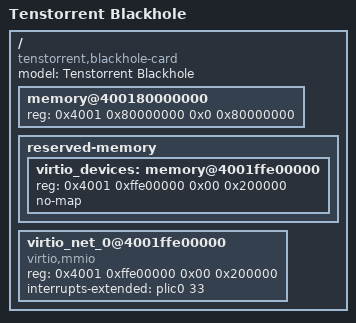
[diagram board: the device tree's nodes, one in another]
// SPDX-License-Identifier: (GPL-2.0 OR MIT)
/dts-v1/;

#include "blackhole.dtsi"

/ {
	model = "Tenstorrent Blackhole";
	compatible = "tenstorrent,blackhole-card", "tenstorrent,blackhole";

	memory@400180000000 {
		device_type = "memory";
		reg = <0x4001 0x80000000 0x0 0x80000000>;
	};

	reserved-memory {
		#address-cells = <2>;
		#size-cells = <2>;
		ranges;

		virtio_devices: memory@4001ffe00000 {
			reg = <0x4001 0xffe00000 0x00 0x200000>;
			no-map;
		};
	};

	virtio_net_0@4001ffe00000 {
		compatible = "virtio,mmio";
		reg = <0x4001 0xffe00000 0x00 0x200000>;
		interrupts-extended = <&plic0 33>;
	};
};
